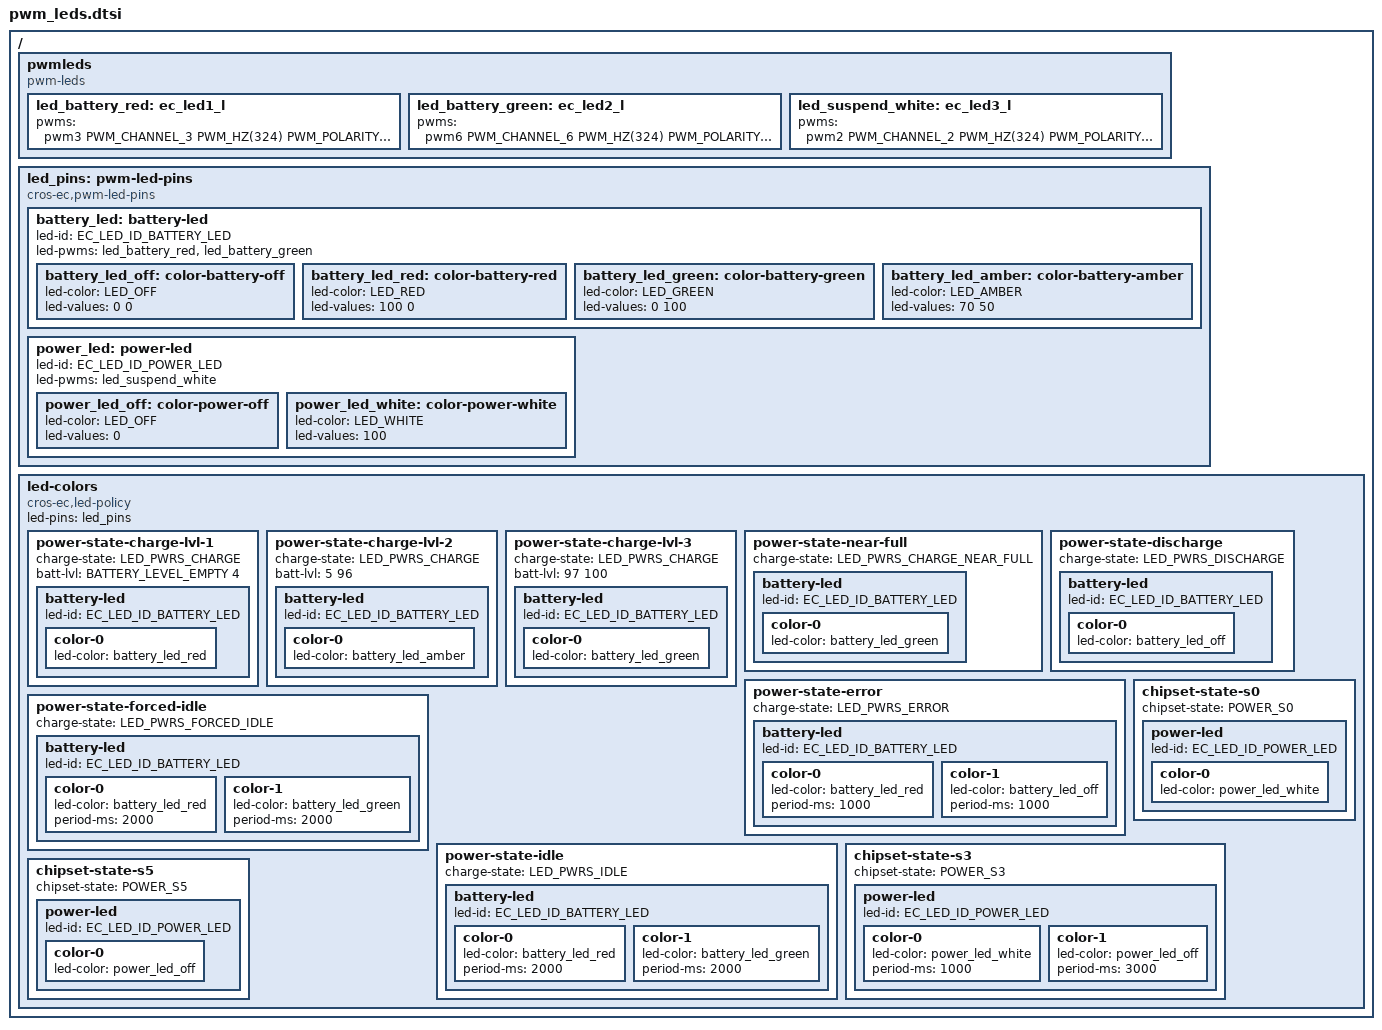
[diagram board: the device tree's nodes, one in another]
/* Copyright 2025 The ChromiumOS Authors
 * Use of this source code is governed by a BSD-style license that can be
 * found in the LICENSE file.
 */
#include <dt-bindings/battery.h>

/ {
	pwmleds {
		compatible = "pwm-leds";

		led_battery_red: ec_led1_l {
			pwms = <&pwm3 PWM_CHANNEL_3 PWM_HZ(324)
				PWM_POLARITY_NORMAL>;
		};
		led_battery_green: ec_led2_l {
			pwms = <&pwm6 PWM_CHANNEL_6 PWM_HZ(324)
				PWM_POLARITY_NORMAL>;
		};
		led_suspend_white: ec_led3_l {
			pwms = <&pwm2 PWM_CHANNEL_2 PWM_HZ(324)
				PWM_POLARITY_NORMAL>;
		};
	};

	led_pins: pwm-led-pins {
		compatible = "cros-ec,pwm-led-pins";

		battery_led: battery-led {
			led-id = "EC_LED_ID_BATTERY_LED";
			led-pwms = <&led_battery_red
				    &led_battery_green>;

			battery_led_off: color-battery-off {
				led-color = "LED_OFF";
				led-values = <0 0>;
			};

			battery_led_red: color-battery-red {
				led-color = "LED_RED";
				led-values = <100 0>;
			};

			battery_led_green: color-battery-green {
				led-color = "LED_GREEN";
				led-values = <0 100>;
			};

			battery_led_amber: color-battery-amber {
				led-color = "LED_AMBER";
				led-values = <70 50>;
			};
		};

		power_led: power-led {
			led-id = "EC_LED_ID_POWER_LED";
			led-pwms = <&led_suspend_white>;

			power_led_off: color-power-off {
				led-color = "LED_OFF";
				led-values = <0>;
			};

			power_led_white: color-power-white {
				led-color = "LED_WHITE";
				led-values = <100>;
			};
		};
	};


	led-colors {
		compatible = "cros-ec,led-policy";
		led-pins = <&led_pins>;

		power-state-charge-lvl-1 {
			charge-state = "LED_PWRS_CHARGE";

			/* Battery display percent range (>= Empty, <= 4%) */
			batt-lvl = <BATTERY_LEVEL_EMPTY 4>;

			battery-led {
				led-id = "EC_LED_ID_BATTERY_LED";

				color-0 {
					led-color = <&battery_led_red>;
				};
			};
		};

		power-state-charge-lvl-2 {
			charge-state = "LED_PWRS_CHARGE";

			/* Battery display percent range (>= 5%, <= 96%) */
			batt-lvl = <5 96>;

			battery-led {
				led-id = "EC_LED_ID_BATTERY_LED";

				color-0 {
					led-color = <&battery_led_amber>;
				};
			};
		};

		power-state-charge-lvl-3 {
			charge-state = "LED_PWRS_CHARGE";

			/* Battery display percent range (>= 97) */
			batt-lvl = <97 100>;

			battery-led {
				led-id = "EC_LED_ID_BATTERY_LED";

				color-0 {
					led-color = <&battery_led_green>;
				};
			};
		};

		power-state-near-full {
			charge-state = "LED_PWRS_CHARGE_NEAR_FULL";

			battery-led {
				led-id = "EC_LED_ID_BATTERY_LED";

				color-0 {
					led-color = <&battery_led_green>;
				};
			};
		};

		power-state-discharge {
			charge-state = "LED_PWRS_DISCHARGE";

			battery-led {
				led-id = "EC_LED_ID_BATTERY_LED";

				color-0 {
					led-color = <&battery_led_off>;
				};
			};
		};

		power-state-error {
			charge-state = "LED_PWRS_ERROR";

			battery-led {
				led-id = "EC_LED_ID_BATTERY_LED";

				/* Red 1 sec on, 1 sec off */
				color-0 {
					led-color = <&battery_led_red>;
					period-ms = <1000>;
				};
				color-1 {
					led-color = <&battery_led_off>;
					period-ms = <1000>;
				};
			};
		};

		power-state-forced-idle {
			charge-state = "LED_PWRS_FORCED_IDLE";

			battery-led {
				led-id = "EC_LED_ID_BATTERY_LED";

				/* Red 2 sec on, Green 2 sec on */
				color-0 {
					led-color = <&battery_led_red>;
					period-ms = <2000>;
				};
				color-1 {
					led-color = <&battery_led_green>;
					period-ms = <2000>;
				};
			};
		};

		power-state-idle {
			charge-state = "LED_PWRS_IDLE";

			battery-led {
				led-id = "EC_LED_ID_BATTERY_LED";

				/* Red 2 sec on, Green 2 sec on */
				color-0 {
					led-color = <&battery_led_red>;
					period-ms = <2000>;
				};
				color-1 {
					led-color = <&battery_led_green>;
					period-ms = <2000>;
				};
			};
		};

		chipset-state-s0 {
			chipset-state = "POWER_S0";

			power-led {
				led-id = "EC_LED_ID_POWER_LED";

				color-0 {
					led-color = <&power_led_white>;
				};
			};
		};

		chipset-state-s3 {
			chipset-state = "POWER_S3";

			power-led {
				led-id = "EC_LED_ID_POWER_LED";

				/* White 1 sec on, 3 sec off */
				color-0 {
					led-color = <&power_led_white>;
					period-ms = <1000>;
				};
				color-1 {
					led-color = <&power_led_off>;
					period-ms = <3000>;
				};
			};
		};

		chipset-state-s5 {
			chipset-state = "POWER_S5";

			power-led {
				led-id = "EC_LED_ID_POWER_LED";

				color-0 {
					led-color = <&power_led_off>;
				};
			};
		};
	};
};
